AUTOSAR XML (schema 00046)
package /ComponentTypes
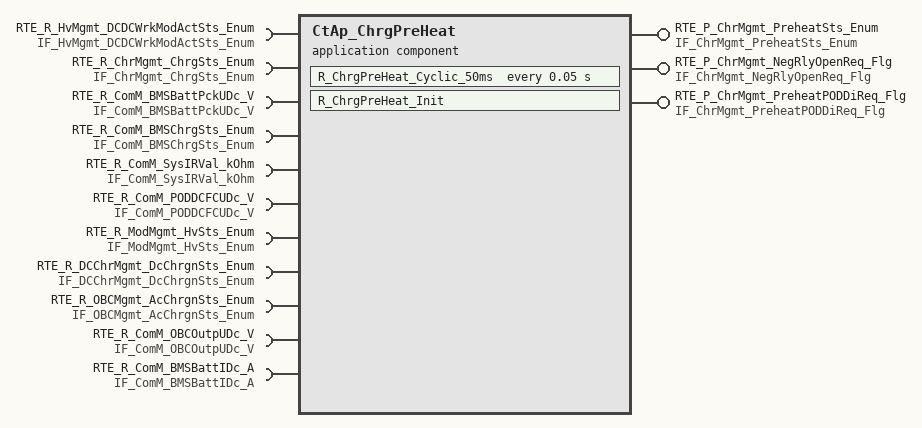
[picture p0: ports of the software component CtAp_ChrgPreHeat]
  application sw component type CtAp_ChrgPreHeat
    provide port RTE_P_ChrMgmt_PreheatSts_Enum: nonqueued-sender-com-spec{data-element=tec_ChrMgmt_PreheatSts_Enum, init-value=0}, provided-interface=IF_ChrMgmt_PreheatSts_Enum
    provide port RTE_P_ChrMgmt_NegRlyOpenReq_Flg: nonqueued-sender-com-spec{data-element=tec_ChrMgmt_NegRlyOpenReq_Flg, init-value=0}, provided-interface=IF_ChrMgmt_NegRlyOpenReq_Flg
    provide port RTE_P_ChrMgmt_PreheatPODDiReq_Flg: nonqueued-sender-com-spec{data-element=tec_ChrMgmt_PreheatPODDiReq_Flg, init-value=0}, provided-interface=IF_ChrMgmt_PreheatPODDiReq_Flg
    11 x require port:
      RTE_R_HvMgmt_DCDCWrkModActSts_Enum: nonqueued-receiver-com-spec{data-element=tec_HvMgmt_DCDCWrkModActSts_Enum, filter=data-filter-type=ALWAYS, init-value=0}, required-interface=IF_HvMgmt_DCDCWrkModActSts_Enum
      RTE_R_ChrMgmt_ChrgSts_Enum: nonqueued-receiver-com-spec{data-element=tec_ChrMgmt_ChrgSts_Enum, filter=data-filter-type=ALWAYS, init-value=0}, required-interface=IF_ChrMgmt_ChrgSts_Enum
      RTE_R_ComM_BMSBattPckUDc_V: nonqueued-receiver-com-spec{data-element=tec_ComM_BMSBattPckUDc_V, filter=data-filter-type=ALWAYS, init-value=0}, required-interface=IF_ComM_BMSBattPckUDc_V
      RTE_R_ComM_BMSChrgSts_Enum: nonqueued-receiver-com-spec{data-element=tec_ComM_BMSChrgSts_Enum, filter=data-filter-type=ALWAYS, init-value=0}, required-interface=IF_ComM_BMSChrgSts_Enum
      RTE_R_ComM_SysIRVal_kOhm: nonqueued-receiver-com-spec{data-element=tec_ComM_SysIRVal_kOhm, filter=data-filter-type=ALWAYS, init-value=0}, required-interface=IF_ComM_SysIRVal_kOhm
      RTE_R_ComM_PODDCFCUDc_V: nonqueued-receiver-com-spec{data-element=tec_ComM_PODDCFCUDc_V, filter=data-filter-type=ALWAYS, init-value=0}, required-interface=IF_ComM_PODDCFCUDc_V
      RTE_R_ModMgmt_HvSts_Enum: nonqueued-receiver-com-spec{data-element=tec_ModMgmt_HvSts_Enum, filter=data-filter-type=ALWAYS, init-value=0}, required-interface=IF_ModMgmt_HvSts_Enum
      RTE_R_DCChrMgmt_DcChrgnSts_Enum: nonqueued-receiver-com-spec{data-element=tec_DCChrMgmt_DcChrgnSts_Enum, filter=data-filter-type=ALWAYS, init-value=0}, required-interface=IF_DCChrMgmt_DcChrgnSts_Enum
      RTE_R_OBCMgmt_AcChrgnSts_Enum: nonqueued-receiver-com-spec{data-element=tec_OBCMgmt_AcChrgnSts_Enum, filter=data-filter-type=ALWAYS, init-value=0}, required-interface=IF_OBCMgmt_AcChrgnSts_Enum
      RTE_R_ComM_OBCOutpUDc_V: nonqueued-receiver-com-spec{data-element=tec_ComM_OBCOutpUDc_V, filter=data-filter-type=ALWAYS, init-value=0}, required-interface=IF_ComM_OBCOutpUDc_V
      RTE_R_ComM_BMSBattIDc_A: nonqueued-receiver-com-spec{data-element=tec_ComM_BMSBattIDc_A, filter=data-filter-type=ALWAYS, init-value=0}, required-interface=IF_ComM_BMSBattIDc_A
    behavior CtAp_ChrgPreHeat_InternalBehavior
      timing event TMT_R_ChrgPreHeat_Cyclic_50ms: start-on-event=R_ChrgPreHeat_Cyclic_50ms, period=0.05
      init event CtAp_ChrgPreHeat_InitEvent: start-on-event=R_ChrgPreHeat_Init
      runnable R_ChrgPreHeat_Cyclic_50ms
        data-receive-point-by-arguments:
          11 x access:
            REC_RTE_R_ChrMgmt_ChrgSts_Enum_tec_ChrMgmt_ChrgSts_Enum: accessed-variable=RTE_R_ChrMgmt_ChrgSts_Enum.tec_ChrMgmt_ChrgSts_Enum
            REC_RTE_R_ComM_BMSBattPckUDc_V_tec_ComM_BMSBattPckUDc_V: accessed-variable=RTE_R_ComM_BMSBattPckUDc_V.tec_ComM_BMSBattPckUDc_V
            REC_RTE_R_ComM_BMSChrgSts_Enum_tec_ComM_BMSChrgSts_Enum: accessed-variable=RTE_R_ComM_BMSChrgSts_Enum.tec_ComM_BMSChrgSts_Enum
            REC_RTE_R_ComM_OBCOutpUDc_V_tec_ComM_OBCOutpUDc_V: accessed-variable=RTE_R_ComM_OBCOutpUDc_V.tec_ComM_OBCOutpUDc_V
            REC_RTE_R_ComM_PODDCFCUDc_V_tec_ComM_PODDCFCUDc_V: accessed-variable=RTE_R_ComM_PODDCFCUDc_V.tec_ComM_PODDCFCUDc_V
            REC_RTE_R_ComM_SysIRVal_kOhm_tec_ComM_SysIRVal_kOhm: accessed-variable=RTE_R_ComM_SysIRVal_kOhm.tec_ComM_SysIRVal_kOhm
            REC_RTE_R_DCChrMgmt_DcChrgnSts_Enum_tec_DCChrMgmt_DcChrgnSts_Enum: accessed-variable=RTE_R_DCChrMgmt_DcChrgnSts_Enum.tec_DCChrMgmt_DcChrgnSts_Enum
            REC_RTE_R_HvMgmt_DCDCWrkModActSts_Enum_tec_HvMgmt_DCDCWrkModActSts_Enum: accessed-variable=RTE_R_HvMgmt_DCDCWrkModActSts_Enum.tec_HvMgmt_DCDCWrkModActSts_Enum
            REC_RTE_R_ModMgmt_HvSts_Enum_tec_ModMgmt_HvSts_Enum: accessed-variable=RTE_R_ModMgmt_HvSts_Enum.tec_ModMgmt_HvSts_Enum
            REC_RTE_R_OBCMgmt_AcChrgnSts_Enum_tec_OBCMgmt_AcChrgnSts_Enum: accessed-variable=RTE_R_OBCMgmt_AcChrgnSts_Enum.tec_OBCMgmt_AcChrgnSts_Enum
            REC_RTE_R_ComM_BMSBattIDc_A_tec_ComM_BMSBattIDc_A: accessed-variable=RTE_R_ComM_BMSBattIDc_A.tec_ComM_BMSBattIDc_A
        data-send-points:
          access SEND_RTE_P_ChrMgmt_NegRlyOpenReq_Flg_tec_ChrMgmt_NegRlyOpenReq_Flg: accessed-variable=RTE_P_ChrMgmt_NegRlyOpenReq_Flg.tec_ChrMgmt_NegRlyOpenReq_Flg
          access SEND_RTE_P_ChrMgmt_PreheatPODDiReq_Flg_tec_ChrMgmt_PreheatPODDiReq_Flg: accessed-variable=RTE_P_ChrMgmt_PreheatPODDiReq_Flg.tec_ChrMgmt_PreheatPODDiReq_Flg
          access SEND_RTE_P_ChrMgmt_PreheatSts_Enum_tec_ChrMgmt_PreheatSts_Enum: accessed-variable=RTE_P_ChrMgmt_PreheatSts_Enum.tec_ChrMgmt_PreheatSts_Enum
      runnable R_ChrgPreHeat_Init
  swc implementation CtAp_ChrgPreHeat_Implementation: behavior=CtAp_ChrgPreHeat_InternalBehavior
    code-descriptors:
      code Default: artifact-descriptors=autosar-engineering-object=category=SWOBJ
